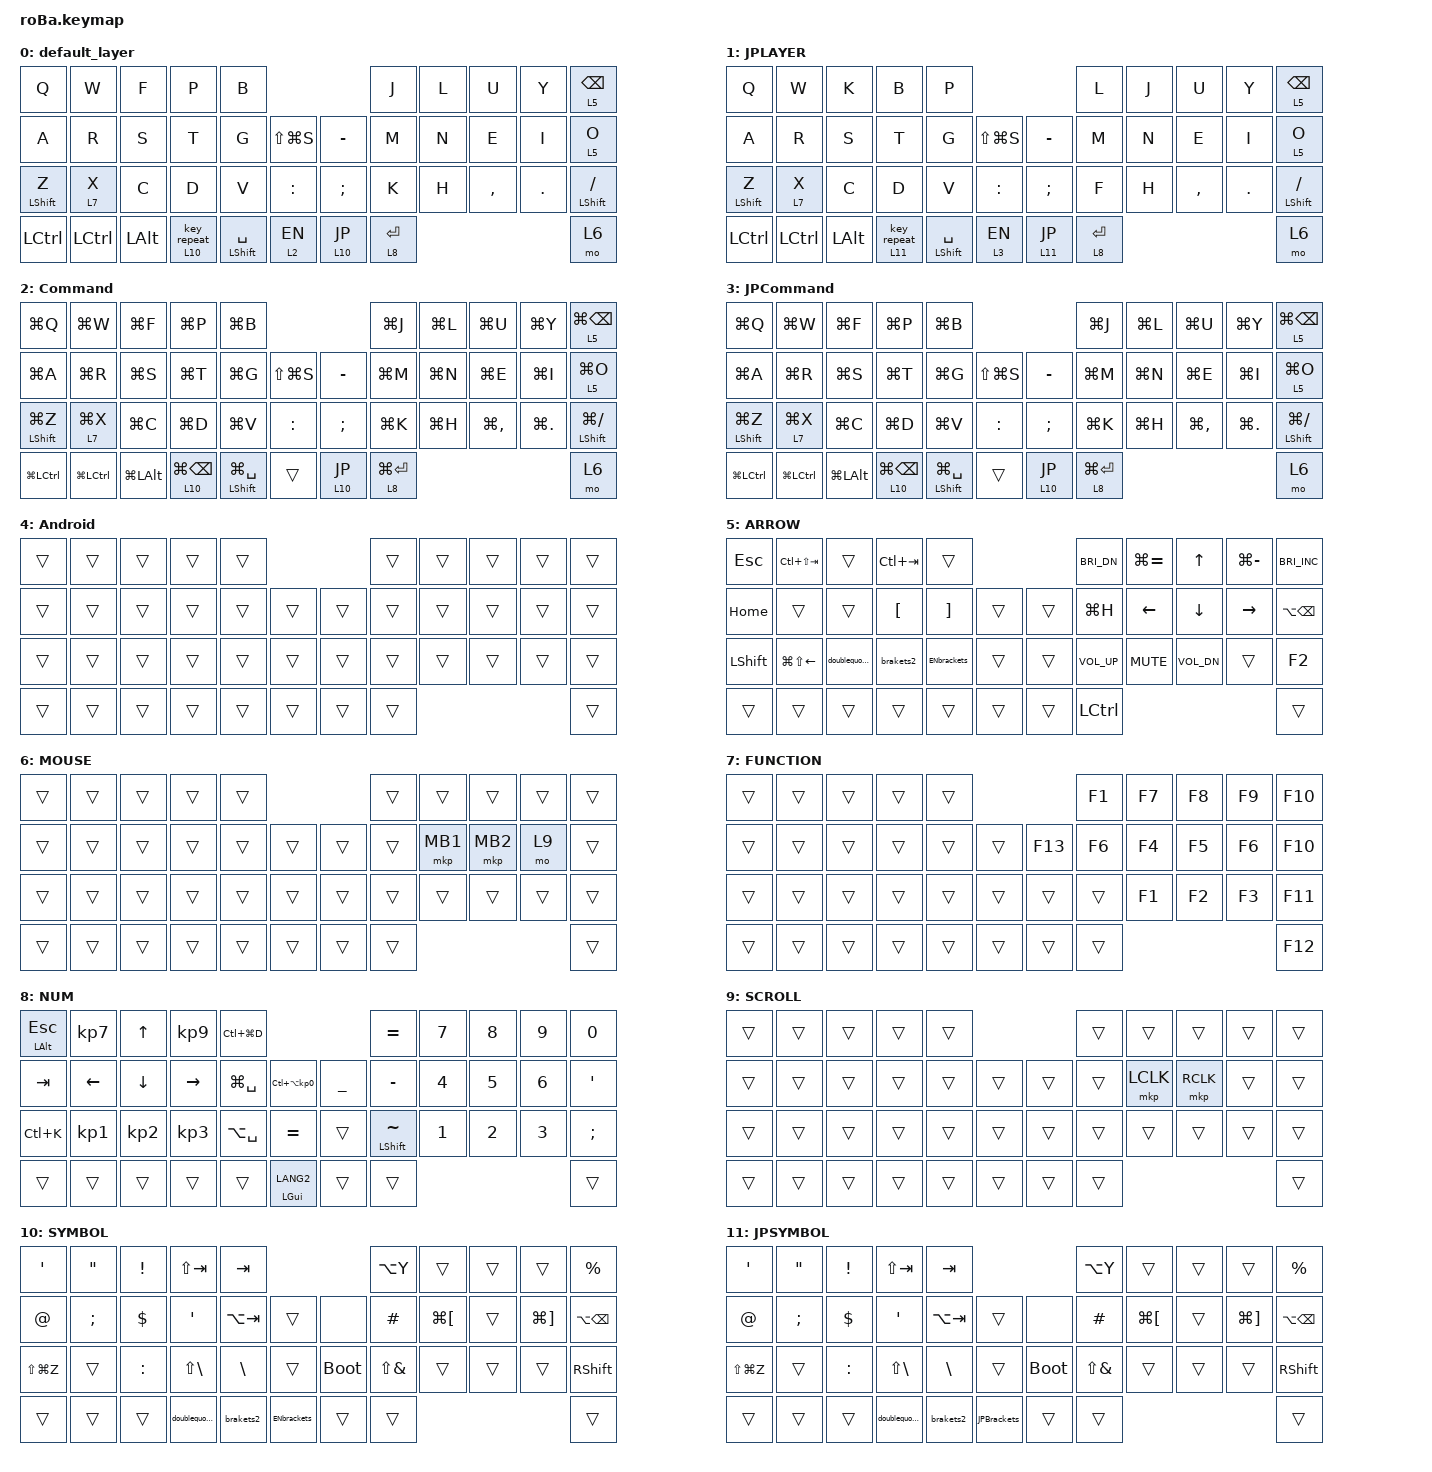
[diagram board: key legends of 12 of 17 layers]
#include <behaviors.dtsi>
#include <dt-bindings/zmk/bt.h>
#include <dt-bindings/zmk/keys.h>
#include <dt-bindings/zmk/pointing.h>

&mt {
    flavor = "tap-preferred";
    quick-tap-ms = <0>;
    tapping-term-ms = <148>;
    require-prior-idle-ms = <0>;
};

&lt {
    flavor = "hold-preferred";
    tapping-term-ms = <130>;
    require-prior-idle-ms = <0>;
};

&trackball {
    automouse-layer = <6>;
    scroll-layers = <9>;

    arrows {
        layers = <12>;
        bindings =
            <&kp RIGHT_ARROW>,
            <&kp LEFT_ARROW>,
            <&kp UP_ARROW>,
            <&kp DOWN_ARROW>;

        tick = <1>;
        wait-ms = <1>;
        tap-ms = <1>;
    };
};

/ {
    combos {
        compatible = "zmk,combos";

        tab {
            bindings = <&kp TAB>;
            key-positions = <11 12>;
        };

        shift_tab {
            bindings = <&kp LS(TAB)>;
            key-positions = <12 13>;
        };

        muhennkann {
            bindings = <&to_layer_0 INT_MUHENKAN>;
            key-positions = <11 10>;
        };

        double_quotation {
            bindings = <&kp DOUBLE_QUOTES>;
            key-positions = <20 21>;
        };

        eq {
            bindings = <&kp EQUAL>;
            key-positions = <24 25>;
        };

        shakamacro {
            bindings = <&shaka6satori>;
            key-positions = <40 29>;
            layers = <0>;
        };

        adv0 {
            bindings = <&adv0andtol0>;
            key-positions = <40 30>;
        };

        adv1 {
            bindings = <&adv1andtol0>;
            key-positions = <40 31>;
        };

        adv2 {
            bindings = <&adv2andtol0>;
            key-positions = <40 32>;
        };

        adv3 {
            bindings = <&adv3andtol0>;
            key-positions = <40 33>;
        };

        lookup {
            bindings = <&kp LG(LC(D))>;
            key-positions = <39 4>;
        };

        spotlight {
            bindings = <&kp LG(SPACE)>;
            key-positions = <39 14>;
        };

        alfred {
            bindings = <&kp LA(SPACE)>;
            key-positions = <39 26>;
        };

        launcher {
            bindings = <&kp LG(H)>;
            key-positions = <21 41 17>;
        };

        three-finger_left_swipe {
            bindings = <&kp LC(LEFT_ARROW)>;
            key-positions = <41 18 21>;
        };

        three-finger_right-swipe {
            bindings = <&kp LC(RIGHT_ARROW)>;
            key-positions = <21 41 20>;
        };

        mission_control {
            bindings = <&kp LC(UP)>;
            key-positions = <7 21 41>;
        };

        dashboard {
            bindings = <&kp LC(LS(DOWN_ARROW))>;
            key-positions = <41 19 21>;
        };

        adv4 {
            bindings = <&adv4andtol1>;
            key-positions = <40 19>;
        };

        tolayer8 {
            bindings = <&to 12>;
            key-positions = <8 40>;
        };

        tolayer0 {
            bindings = <&to 0>;
            key-positions = <40 9>;
        };
    };

    macros {
        to_layer_0: to_layer_0 {
            compatible = "zmk,behavior-macro-one-param";
            #binding-cells = <1>;
            bindings = <&to 0 &macro_param_1to1 &kp MACRO_PLACEHOLDER>;
            label = "TO_LAYER_0";
        };

        ENbrackets: brackets {
            compatible = "zmk,behavior-macro";
            #binding-cells = <0>;
            bindings = <&kp LPAR &kp RPAR &kp LC(B)>;
            label = "BRACKETS";
        };

        brakets2: brakets2 {
            compatible = "zmk,behavior-macro";
            #binding-cells = <0>;
            bindings = <&kp LANG2 &kp LBKT &kp RBKT &kp LC(B)>;
            label = "BRAKETS2";
        };

        doublequotations: doublequotations {
            compatible = "zmk,behavior-macro";
            #binding-cells = <0>;
            bindings = <&kp LANG2 &kp DQT &kp DQT &kp LC(B)>;
            label = "DOUBLEQUOTATIONS";
        };

        shaka6satori: shaka6satori {
            compatible = "zmk,behavior-macro";
            #binding-cells = <0>;
            bindings = <&kp LANGUAGE_2 &kp S &kp H &kp A &kp K &kp A &kp N6 &kp S &kp A &kp T &kp O &kp R &kp I>;
            label = "SHAKA6SATORI";
        };

        adv0andtol0: adv0andtol0 {
            compatible = "zmk,behavior-macro";
            #binding-cells = <0>;
            bindings = <&bt BT_SEL 0>, <&macro_wait_time 200>, <&to 0>;

            label = "ADV0ANDTOL0";
        };

        adv1andtol0: adv1andtol0 {
            compatible = "zmk,behavior-macro";
            #binding-cells = <0>;
            bindings = <&bt BT_SEL 1>, <&macro_wait_time 200>, <&to 0>;

            label = "ADV1ANDTOL0";
        };

        adv2andtol0: adv2andtol0 {
            compatible = "zmk,behavior-macro";
            #binding-cells = <0>;
            bindings = <&bt BT_SEL 2>, <&macro_wait_time 200>, <&to 0>;

            label = "ADV2ANDTOL0";
        };

        adv3andtol0: adv3andtol0 {
            compatible = "zmk,behavior-macro";
            #binding-cells = <0>;
            bindings = <&bt BT_SEL 3>, <&macro_wait_time 200>, <&to 0>;

            label = "ADV3ANDTOL0";
        };

        adv4andtol1: adv4andtol7 {
            compatible = "zmk,behavior-macro";
            #binding-cells = <0>;
            bindings = <&bt BT_SEL 4>, <&macro_wait_time 200>, <&to 4>;

            label = "ADV4ANDTOL7";
        };

        JP: JP {
            compatible = "zmk,behavior-macro";
            #binding-cells = <0>;
            bindings = <&to 1 &kp LANG1>;
            label = "JP";
        };

        EN: En {
            compatible = "zmk,behavior-macro";
            #binding-cells = <0>;
            bindings = <&to 0 &kp LANG2>;
            label = "EN";
        };

        JPBrackets: JPBrackets {
            compatible = "zmk,behavior-macro";
            #binding-cells = <0>;
            bindings = <&kp LPAR &kp RPAR &kp RETURN &kp LC(B)>;
            label = "JPBRACKETS";
        };
    };

    behaviors {
        lt_to_layer_0: lt_to_layer_0 {
            compatible = "zmk,behavior-hold-tap";
            label = "LAYER_TAP_TO_0";
            bindings = <&mo>, <&to_layer_0>;

            #binding-cells = <2>;
            tapping-term-ms = <130>;
            flavor = "tap-preferred";
            quick-tap-ms = <130>;
        };

        arrowlayer: arrowlayer {
            compatible = "zmk,behavior-hold-tap";
            label = "ARROWLAYER";
            bindings = <&mo>, <&kp>;

            #binding-cells = <2>;
            tapping-term-ms = <220>;
            flavor = "tap-preferred";
            retro-tap;
            quick-tap-ms = <0>;
        };

        hold_preferred: hold_preferred {
            compatible = "zmk,behavior-hold-tap";
            label = "HOLD_PREFERRED";
            bindings = <&mo>, <&kp>;

            #binding-cells = <2>;
            tapping-term-ms = <230>;
            flavor = "hold-preferred";
        };

        JpLayer: JpLayer {
            compatible = "zmk,behavior-hold-tap";
            label = "JPLAYER";
            bindings = <&mo>, <&JP>;

            #binding-cells = <2>;
            tapping-term-ms = <230>;
            flavor = "hold-preferred";
        };

        En_Layer: En_Layer {
            compatible = "zmk,behavior-hold-tap";
            label = "EN_LAYER";
            bindings = <&mo>, <&EN>;

            #binding-cells = <2>;
            tapping-term-ms = <230>;
            flavor = "hold-preferred";
        };

        tap_keyrepeat_hold: tap_keyrepeat_hold {
            compatible = "zmk,behavior-hold-tap";
            label = "TAP_KEYREPEAT_HOLD";
            bindings = <&mo>, <&key_repeat>;

            #binding-cells = <2>;
            tapping-term-ms = <230>;
            flavor = "hold-preferred";
        };
    };

    keymap {
        compatible = "zmk,keymap";

        default_layer {
            bindings = <
&kp Q             &kp W             &kp F         &kp P                     &kp B                                               &kp J        &kp L  &kp U      &kp Y       &lt 5 BACKSPACE
&kp A             &kp R             &kp S         &kp T                     &kp G             &kp LS(LG(S))      &kp MINUS      &kp M        &kp N  &kp E      &kp I       &arrowlayer 5 O
&mt LEFT_SHIFT Z  &arrowlayer 7 X   &kp C         &kp D                     &kp V             &kp COLON          &kp SEMICOLON  &kp K        &kp H  &kp COMMA  &kp PERIOD  &mt LEFT_SHIFT SLASH
&kp LCTRL         &kp LEFT_CONTROL  &kp LEFT_ALT  &tap_keyrepeat_hold 10 0  &mt LSHIFT SPACE  &En_Layer 2 0      &JpLayer 10 0  &lt 8 ENTER                                &mo 6
            >;

            sensor-bindings = <&inc_dec_kp PG_UP PAGE_DOWN>;
        };

        JPLAYER {
            bindings = <
&kp Q             &kp W             &kp K         &kp B                     &kp P                                               &kp L        &kp J  &kp U      &kp Y       &lt 5 BACKSPACE
&kp A             &kp R             &kp S         &kp T                     &kp G             &kp LS(LG(S))      &kp MINUS      &kp M        &kp N  &kp E      &kp I       &arrowlayer 5 O
&mt LEFT_SHIFT Z  &lt 7 X           &kp C         &kp D                     &kp V             &kp COLON          &kp SEMICOLON  &kp F        &kp H  &kp COMMA  &kp PERIOD  &mt LEFT_SHIFT SLASH
&kp LCTRL         &kp LEFT_CONTROL  &kp LEFT_ALT  &tap_keyrepeat_hold 11 0  &mt LSHIFT SPACE  &En_Layer 3 0      &JpLayer 11 0  &lt 8 ENTER                                &mo 6
            >;

            sensor-bindings = <&inc_dec_kp PG_UP PAGE_DOWN>;
        };

        Command {
            bindings = <
&kp LG(Q)             &kp LG(W)             &kp LG(F)         &kp LG(P)                         &kp LG(B)                                               &kp LG(J)        &kp LG(L)  &kp LG(U)      &kp LG(Y)       &lt 5 LG(BACKSPACE)
&kp LG(A)             &kp LG(R)             &kp LG(S)         &kp LG(T)                         &kp LG(G)             &kp LS(LG(S))      &kp MINUS      &kp LG(M)        &kp LG(N)  &kp LG(E)      &kp LG(I)       &arrowlayer 5 LG(O)
&mt LEFT_SHIFT LG(Z)  &lt 7 LG(X)           &kp LG(C)         &kp LG(D)                         &kp LG(V)             &kp COLON          &kp SEMICOLON  &kp LG(K)        &kp LG(H)  &kp LG(COMMA)  &kp LG(PERIOD)  &mt LEFT_SHIFT LG(SLASH)
&kp LG(LCTRL)         &kp LG(LEFT_CONTROL)  &kp LG(LEFT_ALT)  &hold_preferred 10 LG(BACKSPACE)  &mt LSHIFT LG(SPACE)  &trans             &JpLayer 10 0  &lt 8 LG(ENTER)                                            &mo 6
            >;

            sensor-bindings = <&inc_dec_kp PG_UP PAGE_DOWN>;
        };

        JPCommand {
            bindings = <
&kp LG(Q)             &kp LG(W)             &kp LG(F)         &kp LG(P)                         &kp LG(B)                                               &kp LG(J)        &kp LG(L)  &kp LG(U)      &kp LG(Y)       &lt 5 LG(BACKSPACE)
&kp LG(A)             &kp LG(R)             &kp LG(S)         &kp LG(T)                         &kp LG(G)             &kp LS(LG(S))      &kp MINUS      &kp LG(M)        &kp LG(N)  &kp LG(E)      &kp LG(I)       &arrowlayer 5 LG(O)
&mt LEFT_SHIFT LG(Z)  &lt 7 LG(X)           &kp LG(C)         &kp LG(D)                         &kp LG(V)             &kp COLON          &kp SEMICOLON  &kp LG(K)        &kp LG(H)  &kp LG(COMMA)  &kp LG(PERIOD)  &mt LEFT_SHIFT LG(SLASH)
&kp LG(LCTRL)         &kp LG(LEFT_CONTROL)  &kp LG(LEFT_ALT)  &hold_preferred 10 LG(BACKSPACE)  &mt LSHIFT LG(SPACE)  &trans             &JpLayer 10 0  &lt 8 LG(ENTER)                                            &mo 6
            >;

            sensor-bindings = <&inc_dec_kp PG_UP PAGE_DOWN>;
        };

        Android {
            bindings = <
&trans  &trans  &trans  &trans  &trans                      &trans  &trans  &trans  &trans  &trans
&trans  &trans  &trans  &trans  &trans  &trans      &trans  &trans  &trans  &trans  &trans  &trans
&trans  &trans  &trans  &trans  &trans  &trans      &trans  &trans  &trans  &trans  &trans  &trans
&trans  &trans  &trans  &trans  &trans  &trans      &trans  &trans                          &trans
            >;
        };

        ARROW {
            bindings = <
&kp ESCAPE      &kp LC(LS(TAB))         &trans             &kp LC(TAB)  &trans                           &kp C_BRI_DN     &kp LG(EQUAL)   &kp UP_ARROW    &kp LG(MINUS)    &kp C_BRI_INC
&kp HOME        &trans                  &trans             &kp LBKT     &kp RBKT     &trans      &trans  &kp LG(H)        &kp LEFT_ARROW  &kp DOWN_ARROW  &kp RIGHT_ARROW  &kp LA(BACKSPACE)
&kp LEFT_SHIFT  &kp LG(LS(LEFT_ARROW))  &doublequotations  &brakets2    &ENbrackets  &trans      &trans  &kp C_VOLUME_UP  &kp K_MUTE      &kp C_VOL_DN    &trans           &kp F2
&trans          &trans                  &trans             &trans       &trans       &trans      &trans  &kp LCTRL                                                         &trans
            >;

            sensor-bindings = <&inc_dec_kp LC(PAGE_UP) LC(PAGE_DOWN)>;
        };

        MOUSE {
            bindings = <
&trans  &trans  &trans  &trans  &trans                      &trans  &trans    &trans    &trans  &trans
&trans  &trans  &trans  &trans  &trans  &trans      &trans  &trans  &mkp MB1  &mkp MB2  &mo 9   &trans
&trans  &trans  &trans  &trans  &trans  &trans      &trans  &trans  &trans    &trans    &trans  &trans
&trans  &trans  &trans  &trans  &trans  &trans      &trans  &trans                              &trans
            >;
        };

        FUNCTION {
            bindings = <
&trans  &trans  &trans  &trans  &trans                       &kp F1  &kp F7  &kp F8  &kp F9  &kp F10
&trans  &trans  &trans  &trans  &trans  &trans      &kp F13  &kp F6  &kp F4  &kp F5  &kp F6  &kp F10
&trans  &trans  &trans  &trans  &trans  &trans      &trans   &trans  &kp F1  &kp F2  &kp F3  &kp F11
&trans  &trans  &trans  &trans  &trans  &trans      &trans   &trans                          &kp F12
            >;
        };

        NUM {
            bindings = <
&mt LEFT_ALT ESC  &kp KP_NUMBER_7  &kp UP_ARROW     &kp KP_NUMBER_9  &kp LC(LG(D))                                               &kp EQUAL             &kp NUMBER_7  &kp NUMBER_8  &kp NUMBER_9  &kp NUMBER_0
&kp TAB           &kp LEFT         &kp DOWN_ARROW   &kp RIGHT        &kp LG(SPACE)  &kp LC(LA(KP_NUMBER_0))      &kp UNDERSCORE  &kp MINUS             &kp NUMBER_4  &kp NUMBER_5  &kp NUMBER_6  &kp SINGLE_QUOTE
&kp LC(K)         &kp KP_NUMBER_1  &kp KP_NUMBER_2  &kp KP_NUMBER_3  &kp LA(SPACE)  &kp EQUAL                    &trans          &mt LEFT_SHIFT TILDE  &kp NUMBER_1  &kp NUMBER_2  &kp NUMBER_3  &kp SEMICOLON
&trans            &trans           &trans           &trans           &trans         &mt LGUI LANG2               &trans          &trans                                                          &trans
            >;
        };

        SCROLL {
            bindings = <
&trans  &trans  &trans  &trans  &trans                      &trans  &trans     &trans     &trans  &trans
&trans  &trans  &trans  &trans  &trans  &trans      &trans  &trans  &mkp LCLK  &mkp RCLK  &trans  &trans
&trans  &trans  &trans  &trans  &trans  &trans      &trans  &trans  &trans     &trans     &trans  &trans
&trans  &trans  &trans  &trans  &trans  &trans      &trans  &trans                                &trans
            >;
        };

        SYMBOL {
            bindings = <
&kp SINGLE_QUOTE  &kp DQT   &kp EXCL   &kp LS(TAB)        &kp TAB                                      &kp LA(Y)          &trans        &trans  &trans        &kp PRCNT
&kp AT            &kp SEMI  &kp DLLR   &kp SINGLE_QUOTE   &kp LA(TAB)    &trans           &none        &kp HASH           &kp LG(LBKT)  &trans  &kp LG(RBKT)  &kp LA(BACKSPACE)
&kp LS(LG(Z))     &trans    &kp COLON  &kp LS(BSLH)       &kp BACKSLASH  &trans           &bootloader  &kp LS(AMPERSAND)  &trans        &trans  &trans        &kp RIGHT_SHIFT
&trans            &trans    &trans     &doublequotations  &brakets2      &ENbrackets      &trans       &trans                                                 &trans
            >;
        };

        JPSYMBOL {
            bindings = <
&kp SINGLE_QUOTE  &kp DQT   &kp EXCL   &kp LS(TAB)        &kp TAB                                      &kp LA(Y)          &trans        &trans  &trans        &kp PRCNT
&kp AT            &kp SEMI  &kp DLLR   &kp SINGLE_QUOTE   &kp LA(TAB)    &trans           &none        &kp HASH           &kp LG(LBKT)  &trans  &kp LG(RBKT)  &kp LA(BACKSPACE)
&kp LS(LG(Z))     &trans    &kp COLON  &kp LS(BSLH)       &kp BACKSLASH  &trans           &bootloader  &kp LS(AMPERSAND)  &trans        &trans  &trans        &kp RIGHT_SHIFT
&trans            &trans    &trans     &doublequotations  &brakets2      &JPBrackets      &trans       &trans                                                 &trans
            >;
        };

        layer_8 {
            bindings = <
&kp Q   &kp F   &kp R   &kp W   &kp L                          &kp J    &kp G  &kp U      &kp Y    &kp BACKSPACE
&kp A   &kp H   &kp N   &kp S   &kp M   &kp H       &kp H      &kp K    &kp T  &kp E      &kp I    &arrowlayer 15 O
&kp Z   &kp X   &kp C   &kp V   &kp B   &kp N       &kp SEMI   &kp P    &kp D  &kp COMMA  &kp DOT  &kp FSLH
&trans  &trans  &trans  &trans  &trans  &trans      &kp SPACE  &kp RET                             &kp RSHFT
            >;
        };

        layer_9 {
            bindings = <
&trans  &trans  &trans  &trans  &trans                       &kp F1  &kp F7  &kp F8  &kp F9  &kp F10
&trans  &trans  &trans  &trans  &trans  &trans      &kp F13  &kp F6  &kp F4  &kp F5  &kp F6  &kp F10
&trans  &trans  &trans  &trans  &trans  &trans      &trans   &trans  &kp F1  &kp F2  &kp F3  &kp F11
&trans  &trans  &trans  &trans  &trans  &trans      &trans   &trans                          &kp F12
            >;
        };

        layer_10 {
            bindings = <
&mt LEFT_ALT ESC  &kp KP_NUMBER_7  &kp UP_ARROW     &kp KP_NUMBER_9  &kp LC(LG(D))                                               &kp EQUAL             &kp NUMBER_7  &kp NUMBER_8  &kp NUMBER_9  &kp NUMBER_0
&kp TAB           &kp LEFT         &kp DOWN_ARROW   &kp RIGHT        &kp LG(SPACE)  &kp LC(LA(KP_NUMBER_0))      &kp UNDERSCORE  &kp MINUS             &kp NUMBER_4  &kp NUMBER_5  &kp NUMBER_6  &kp SINGLE_QUOTE
&kp LC(K)         &kp KP_NUMBER_1  &kp KP_NUMBER_2  &kp KP_NUMBER_3  &kp LA(SPACE)  &kp EQUAL                    &trans          &mt LEFT_SHIFT TILDE  &kp NUMBER_1  &kp NUMBER_2  &kp NUMBER_3  &kp SEMICOLON
&trans            &trans           &trans           &trans           &trans         &trans                       &trans          &trans                                                          &trans
            >;
        };

        layer_11 {
            bindings = <
&kp ESCAPE      &kp LC(LS(TAB))         &trans             &kp LC(TAB)  &trans                           &kp C_BRI_DN     &kp LG(EQUAL)   &kp UP_ARROW    &kp LG(MINUS)    &kp C_BRI_INC
&kp HOME        &trans                  &trans             &kp LBKT     &kp RBKT     &trans      &trans  &kp LG(H)        &kp LEFT_ARROW  &kp DOWN_ARROW  &kp RIGHT_ARROW  &kp LA(BACKSPACE)
&kp LEFT_SHIFT  &kp LG(LS(LEFT_ARROW))  &doublequotations  &brakets2    &ENbrackets  &trans      &trans  &kp C_VOLUME_UP  &kp K_MUTE      &kp C_VOL_DN    &trans           &kp F2
&trans          &trans                  &trans             &trans       &trans       &trans      &trans  &kp LCTRL                                                         &trans
            >;

            sensor-bindings = <&inc_dec_kp LC(PAGE_UP) LC(PAGE_DOWN)>;
        };

        layer_12 {
            bindings = <
&kp SINGLE_QUOTE  &kp DQT   &kp EXCL   &kp LS(TAB)        &kp TAB                                         &kp LA(Y)          &trans        &trans  &trans        &kp PRCNT
&kp AT            &kp SEMI  &kp DLLR   &trans             &kp LA(TAB)    &trans           &bt BT_CLR_ALL  &kp HASH           &kp LG(LBKT)  &trans  &kp LG(RBKT)  &kp LA(BACKSPACE)
&kp LS(LG(Z))     &trans    &kp COLON  &kp LS(BSLH)       &kp BACKSLASH  &trans           &bootloader     &kp LS(AMPERSAND)  &trans        &trans  &trans        &kp RIGHT_SHIFT
&trans            &trans    &trans     &doublequotations  &brakets2      &ENbrackets      &trans          &trans                                                 &trans
            >;
        };
    };
};
